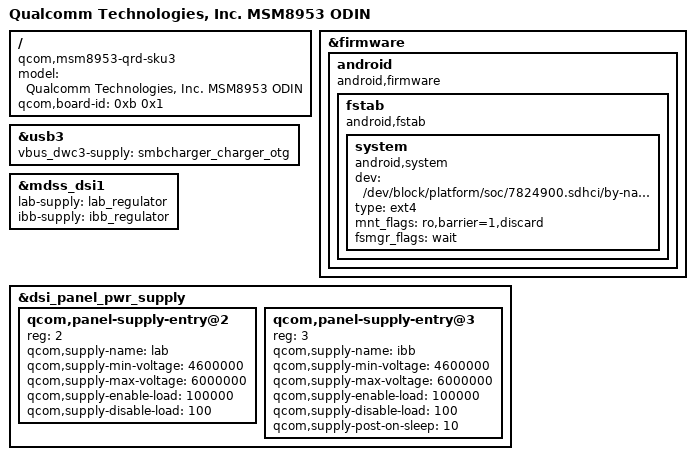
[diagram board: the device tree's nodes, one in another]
/*
 * Copyright (c) 2015-2016, The Linux Foundation. All rights reserved.
 *
 * This program is free software; you can redistribute it and/or modify
 * it under the terms of the GNU General Public License version 2 and
 * only version 2 as published by the Free Software Foundation.
 *
 * This program is distributed in the hope that it will be useful,
 * but WITHOUT ANY WARRANTY; without even the implied warranty of
 * MERCHANTABILITY or FITNESS FOR A PARTICULAR PURPOSE.  See the
 * GNU General Public License for more details.
 */

/dts-v1/;

#define CONFIG_VENDOR_SMARTISAN
#define CONFIG_VENDOR_SMARTISAN_ODIN

#include "msm8953.dtsi"
#include "msm-pmi8950.dtsi"

/ {
	model = "Qualcomm Technologies, Inc. MSM8953 ODIN";
	compatible = "qcom,msm8953-qrd-sku3",
		   "qcom,msm8953-qrd", "qcom,msm8953", "qcom,qrd", "qcom,odin", "qcom,odin-p1";
	qcom,board-id= <0xb 0x1>;
};

#include "msm8953-qrd-sku3.dtsi"
#include "u3-p1-msm8953-special-odin.dtsi"

&firmware {
	android {
		compatible = "android,firmware";
		fstab {
			compatible = "android,fstab";

			system {
				compatible = "android,system";
				dev = "/dev/block/platform/soc/7824900.sdhci/by-name/system";
				type = "ext4";
				mnt_flags = "ro,barrier=1,discard";
				fsmgr_flags = "wait";
				status = "ok";
			};

			/delete-node/ vendor;
		};
	};
};

&usb3 {
	vbus_dwc3-supply = <&smbcharger_charger_otg>;
};

&mdss_dsi1 {
	lab-supply = <&lab_regulator>;
	ibb-supply = <&ibb_regulator>;
};

&dsi_panel_pwr_supply {
	qcom,panel-supply-entry@2 {
		reg = <2>;
		qcom,supply-name = "lab";
		qcom,supply-min-voltage = <4600000>;
		qcom,supply-max-voltage = <6000000>;
		qcom,supply-enable-load = <100000>;
		qcom,supply-disable-load = <100>;
	};

	qcom,panel-supply-entry@3 {
		reg = <3>;
		qcom,supply-name = "ibb";
		qcom,supply-min-voltage = <4600000>;
		qcom,supply-max-voltage = <6000000>;
		qcom,supply-enable-load = <100000>;
		qcom,supply-disable-load = <100>;
		qcom,supply-post-on-sleep = <10>;
	};
};
